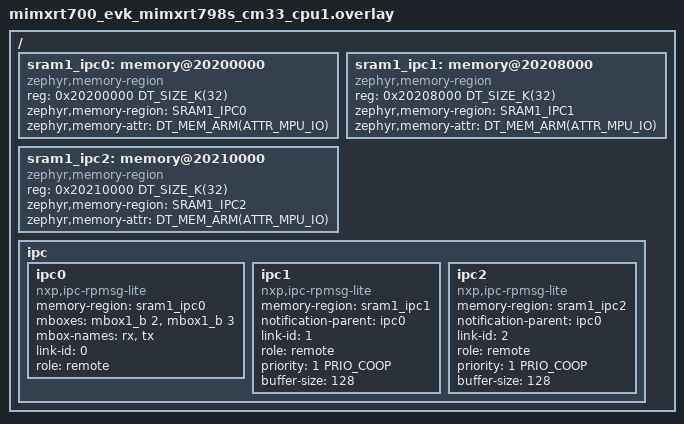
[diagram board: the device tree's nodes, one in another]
/*
 * Copyright 2026 NXP
 *
 * SPDX-License-Identifier: Apache-2.0
 */

#include <zephyr/dt-bindings/ipc_service/static_vrings.h>
#include <zephyr/dt-bindings/memory-attr/memory-attr-arm.h>

/ {
	/* Define memory regions for IPC */
	sram1_ipc0: memory@20200000 {
		compatible = "zephyr,memory-region", "mmio-sram";
		reg = <0x20200000 DT_SIZE_K(32)>;
		zephyr,memory-region = "SRAM1_IPC0";
		zephyr,memory-attr = <DT_MEM_ARM(ATTR_MPU_IO)>;
	};

	sram1_ipc1: memory@20208000 {
		compatible = "zephyr,memory-region", "mmio-sram";
		reg = <0x20208000 DT_SIZE_K(32)>;
		zephyr,memory-region = "SRAM1_IPC1";
		zephyr,memory-attr = <DT_MEM_ARM(ATTR_MPU_IO)>;
	};

	sram1_ipc2: memory@20210000 {
		compatible = "zephyr,memory-region", "mmio-sram";
		reg = <0x20210000 DT_SIZE_K(32)>;
		zephyr,memory-region = "SRAM1_IPC2";
		zephyr,memory-attr = <DT_MEM_ARM(ATTR_MPU_IO)>;
	};

	ipc {
		/delete-node/ ipc0;

		ipc0: ipc0 {
			compatible = "nxp,ipc-rpmsg-lite";
			memory-region = <&sram1_ipc0>;
			mboxes = <&mbox1_b 2>, <&mbox1_b 3>;
			mbox-names = "rx", "tx";
			link-id = <0>;
			role = "remote";
			status = "okay";
		};

		ipc1: ipc1 {
			compatible = "nxp,ipc-rpmsg-lite";
			memory-region = <&sram1_ipc1>;
			notification-parent = <&ipc0>;
			link-id = <1>;
			role = "remote";
			priority = <1 PRIO_COOP>;
			buffer-size = <128>;
			status = "okay";
		};

		ipc2: ipc2 {
			compatible = "nxp,ipc-rpmsg-lite";
			memory-region = <&sram1_ipc2>;
			notification-parent = <&ipc0>;
			link-id = <2>;
			role = "remote";
			priority = <1 PRIO_COOP>;
			buffer-size = <128>;
			status = "okay";
		};
	};
};
